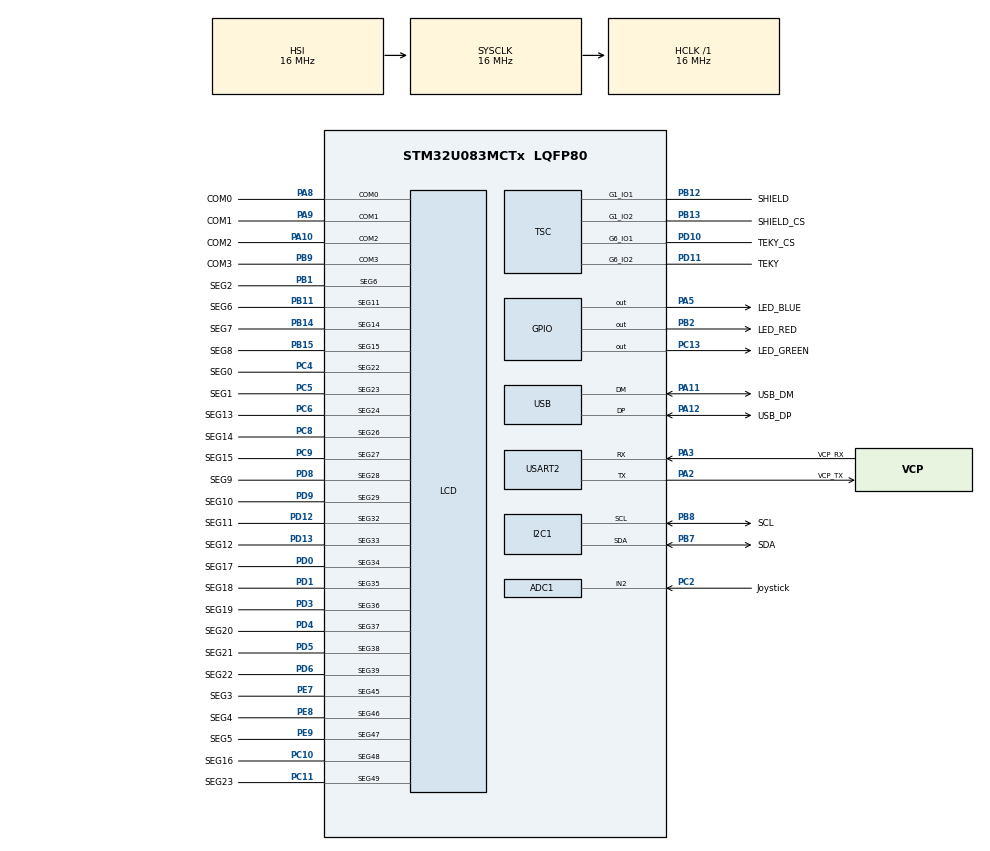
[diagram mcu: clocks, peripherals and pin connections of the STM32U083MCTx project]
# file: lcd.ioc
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ADC1.Channel-1\#ChannelRegularConversion=ADC_CHANNEL_2
ADC1.NbrOfConversionFlag=1
ADC1.Rank-1\#ChannelRegularConversion=1
ADC1.RankArg-1\#ChannelRegularConversion=ADC_REGULAR_RANK_1
ADC1.SamplingTime-1\#ChannelRegularConversion=ADC_SAMPLINGTIME_COMMON_1
ADC1.SelectedChannel=ADC_CHANNEL_2
ADC1.master=1
Mcu.Family=STM32U0
Mcu.Name=STM32U083MCTx
Mcu.Package=LQFP80
NVIC.PriorityGroup=NVIC_PRIORITYGROUP_2
PA10.GPIO_Label=COM2
PA10.Mode=1/4 Duty Cycle
PA10.Signal=LCD_COM2
PA11\ [PA9].GPIO_Label=USB_DM
PA11\ [PA9].Mode=Device
PA11\ [PA9].Signal=USB_DM
PA12\ [PA10].GPIO_Label=USB_DP
PA12\ [PA10].Mode=Device
PA12\ [PA10].Signal=USB_DP
PA13\ (SWDIO).GPIO_Label=SWDIO
PA13\ (SWDIO).Mode=Serial_Wire
PA13\ (SWDIO).Signal=DEBUG_JTMS-SWDIO
PA14\ (SWCLK).GPIO_Label=SWCLK
PA14\ (SWCLK).Mode=Serial_Wire
PA14\ (SWCLK).Signal=DEBUG_JTCK-SWCLK
PA2.GPIO_Label=VCP_TX
PA2.Mode=Asynchronous
PA2.Signal=USART2_TX
PA3.GPIO_Label=VCP_RX
PA3.Mode=Asynchronous
PA3.Signal=USART2_RX
PA5.GPIO_Label=LED_BLUE
PA5.Signal=GPIO_Output
PA8.GPIO_Label=COM0
PA8.Mode=1/4 Duty Cycle
PA8.Signal=LCD_COM0
PA9.GPIO_Label=COM1
PA9.Mode=1/4 Duty Cycle
PA9.Signal=LCD_COM1
PB1.GPIO_Label=SEG2
PB1.Mode=SEG6
PB1.Signal=LCD_SEG6
PB11.GPIO_Label=SEG6
PB11.Mode=SEG11
PB11.Signal=LCD_SEG11
PB12.GPIO_Label=SHIELD
PB12.Mode=G1_IO1-Sampling
PB12.Signal=TSC_G1_IO1
PB13.GPIO_Label=SHIELD_CS
PB13.Mode=G1_IO2-Channel
PB13.Signal=TSC_G1_IO2
PB14.GPIO_Label=SEG7
PB14.Mode=SEG14
PB14.Signal=LCD_SEG14
PB15.GPIO_Label=SEG8
PB15.Mode=SEG15
PB15.Signal=LCD_SEG15
PB2.GPIO_Label=LED_RED
PB2.Signal=GPIO_Output
PB7.GPIO_Label=SDA
PB7.Mode=I2C
PB7.Signal=I2C1_SDA
PB8.GPIO_Label=SCL
PB8.Mode=I2C
PB8.Signal=I2C1_SCL
PB9.GPIO_Label=COM3
PB9.Mode=1/4 Duty Cycle
PB9.Signal=LCD_COM3
PC10.GPIO_Label=SEG16
PC10.Mode=SEG48
PC10.Signal=LCD_SEG48
PC11.GPIO_Label=SEG23
PC11.Mode=SEG49
PC11.Signal=LCD_SEG49
PC13.GPIO_Label=LED_GREEN
PC13.Signal=GPIO_Output
PC14-OSC32_IN.GPIO_Label=OSC32_IN
PC14-OSC32_IN.Mode=LSE-External-Oscillator
PC14-OSC32_IN.Signal=RCC_OSC32_IN
PC15-OSC32_OUT.GPIO_Label=OSC32_OUT
PC15-OSC32_OUT.Mode=LSE-External-Oscillator
PC15-OSC32_OUT.Signal=RCC_OSC32_OUT
PC2.GPIO_Label=Joystick
PC2.Mode=IN2
PC2.Signal=ADC1_IN2
PC4.GPIO_Label=SEG0
PC4.Mode=SEG22
PC4.Signal=LCD_SEG22
PC5.GPIO_Label=SEG1
PC5.Mode=SEG23
PC5.Signal=LCD_SEG23
PC6.GPIO_Label=SEG13
PC6.Mode=SEG24
PC6.Signal=LCD_SEG24
PC8.GPIO_Label=SEG14
PC8.Mode=SEG26
PC8.Signal=LCD_SEG26
PC9.GPIO_Label=SEG15
PC9.Mode=SEG27
PC9.Signal=LCD_SEG27
PD0.GPIO_Label=SEG17
PD0.Mode=SEG34
PD0.Signal=LCD_SEG34
PD1.GPIO_Label=SEG18
PD1.Mode=SEG35
PD1.Signal=LCD_SEG35
PD10.GPIO_Label=TEKY_CS
PD10.Mode=G6_IO1-Sampling
PD10.Signal=TSC_G6_IO1
PD11.GPIO_Label=TEKY
PD11.Mode=G6_IO2-Shield
PD11.Signal=TSC_G6_IO2
PD12.GPIO_Label=SEG11
PD12.Mode=SEG32
PD12.Signal=LCD_SEG32
PD13.GPIO_Label=SEG12
PD13.Mode=SEG33
PD13.Signal=LCD_SEG33
PD3.GPIO_Label=SEG19
PD3.Mode=SEG36
PD3.Signal=LCD_SEG36
PD4.GPIO_Label=SEG20
PD4.Mode=SEG37
PD4.Signal=LCD_SEG37
PD5.GPIO_Label=SEG21
PD5.Mode=SEG38
PD5.Signal=LCD_SEG38
PD6.GPIO_Label=SEG22
PD6.Mode=SEG39
PD6.Signal=LCD_SEG39
PD8.GPIO_Label=SEG9
PD8.Mode=SEG28
PD8.Signal=LCD_SEG28
PD9.GPIO_Label=SEG10
PD9.Mode=SEG29
PD9.Signal=LCD_SEG29
PE7.GPIO_Label=SEG3
PE7.Mode=SEG45
PE7.Signal=LCD_SEG45
PE8.GPIO_Label=SEG4
PE8.Mode=SEG46
PE8.Signal=LCD_SEG46
PE9.GPIO_Label=SEG5
PE9.Mode=SEG47
PE9.Signal=LCD_SEG47
PF0-OSC_IN.GPIO_Label=OSC_IN
PF0-OSC_IN.Mode=HSE-External-Oscillator
PF0-OSC_IN.Signal=RCC_OSC_IN
PF1-OSC_OUT.GPIO_Label=OSC_OUT
PF1-OSC_OUT.Mode=HSE-External-Oscillator
PF1-OSC_OUT.Signal=RCC_OSC_OUT
ProjectManager.HeapSize=0x200
ProjectManager.StackSize=0x400
ProjectManager.TargetToolchain=STM32CubeIDE
RCC.AHBFreq_Value=16000000
RCC.CortexFreq_Value=16000000
RCC.HCLKFreq_Value=16000000
RCC.HSE_VALUE=4000000
RCC.HSI48_VALUE=48000000
RCC.HSI_VALUE=16000000
RCC.MSIClockRangeVal=RCC_MSIRANGE_11
RCC.MSI_VALUE=48000000
RCC.SYSCLKFreq_VALUE=16000000
RCC.USBFreq_Value=48000000
RCC.VCOOutputFreq_Value=64000000
USART2.VirtualMode-Asynchronous=VM_ASYNC
USB.VirtualMode=Device_Only
VP_PWR_VS_SECSignals.Mode=Security/Privilege
board=STM32U083C-DK

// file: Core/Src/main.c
/* USER CODE BEGIN Header */
/**
  ******************************************************************************
  * @file           : main.c
  * @brief          : Main program body
  ******************************************************************************
  * @attention
  *
  * Copyright (c) 2024 STMicroelectronics.
  * All rights reserved.
  *
  * This software is licensed under terms that can be found in the LICENSE file
  * in the root directory of this software component.
  * If no LICENSE file comes with this software, it is provided AS-IS.
  *
  ******************************************************************************
  */
/* USER CODE END Header */
#include "main.h"
#include "stm32u083c_discovery.h"
#include "stm32u083c_discovery_glass_lcd.h"
/* USER CODE BEGIN Includes */
uint8_t a[]= "hello ";
/* USER CODE END Includes */

ADC_HandleTypeDef hadc1;

I2C_HandleTypeDef hi2c1;

LCD_HandleTypeDef hlcd;

TSC_HandleTypeDef htsc;

UART_HandleTypeDef huart2;

PCD_HandleTypeDef hpcd_USB_DRD_FS;

void SystemClock_Config(void);
static void MX_GPIO_Init(void);
static void MX_ADC1_Init(void);
static void MX_I2C1_Init(void);
static void MX_LCD_Init(void);
static void MX_TSC_Init(void);
static void MX_USART2_UART_Init(void);
static void MX_USB_PCD_Init(void);

int main(void)
{

  /* MCU Configuration--------------------------------------------------------*/

  /* Reset of all peripherals, Initializes the Flash interface and the Systick. */
  HAL_Init();

  /* Configure the system clock */
  SystemClock_Config();

  /* Initialize all configured peripherals */
  MX_GPIO_Init();
  MX_ADC1_Init();
  MX_I2C1_Init();
 // MX_LCD_Init();
  MX_TSC_Init();
  MX_USART2_UART_Init();
  MX_USB_PCD_Init();
  /* USER CODE BEGIN 2 */
BSP_LCD_GLASS_Init();
BSP_LCD_GLASS_ScrollSentence(a, 1000, SCROLL_SPEED_LOW);
  /* USER CODE END 2 */

  /* Infinite loop */
  while (1)
  {

  }
}

void SystemClock_Config(void)
{
  RCC_OscInitTypeDef RCC_OscInitStruct = {0};
  RCC_ClkInitTypeDef RCC_ClkInitStruct = {0};

  /** Configure the main internal regulator output voltage
  */
  HAL_PWREx_ControlVoltageScaling(PWR_REGULATOR_VOLTAGE_SCALE2);

  /** Initializes the RCC Oscillators according to the specified parameters
  * in the RCC_OscInitTypeDef structure.
  */
  RCC_OscInitStruct.OscillatorType = RCC_OSCILLATORTYPE_HSI|RCC_OSCILLATORTYPE_MSI;
  RCC_OscInitStruct.HSIState = RCC_HSI_ON;
  RCC_OscInitStruct.HSICalibrationValue = RCC_HSICALIBRATION_DEFAULT;
  RCC_OscInitStruct.MSIState = RCC_MSI_ON;
  RCC_OscInitStruct.MSICalibrationValue = RCC_MSICALIBRATION_DEFAULT;
  RCC_OscInitStruct.MSIClockRange = RCC_MSIRANGE_11;
  RCC_OscInitStruct.PLL.PLLState = RCC_PLL_NONE;
  if (HAL_RCC_OscConfig(&RCC_OscInitStruct) != HAL_OK)
  {
    Error_Handler();
  }

  /** Initializes the CPU, AHB and APB buses clocks
  */
  RCC_ClkInitStruct.ClockType = RCC_CLOCKTYPE_HCLK|RCC_CLOCKTYPE_SYSCLK
                              |RCC_CLOCKTYPE_PCLK1;
  RCC_ClkInitStruct.SYSCLKSource = RCC_SYSCLKSOURCE_HSI;
  RCC_ClkInitStruct.AHBCLKDivider = RCC_SYSCLK_DIV1;
  RCC_ClkInitStruct.APB1CLKDivider = RCC_HCLK_DIV1;

  if (HAL_RCC_ClockConfig(&RCC_ClkInitStruct, FLASH_LATENCY_1) != HAL_OK)
  {
    Error_Handler();
  }
}

static void MX_ADC1_Init(void)
{

  ADC_ChannelConfTypeDef sConfig = {0};

  /** Configure the global features of the ADC (Clock, Resolution, Data Alignment and number of conversion)
  */
  hadc1.Instance = ADC1;
  hadc1.Init.ClockPrescaler = ADC_CLOCK_SYNC_PCLK_DIV1;
  hadc1.Init.Resolution = ADC_RESOLUTION_12B;
  hadc1.Init.DataAlign = ADC_DATAALIGN_RIGHT;
  hadc1.Init.ScanConvMode = ADC_SCAN_DISABLE;
  hadc1.Init.EOCSelection = ADC_EOC_SINGLE_CONV;
  hadc1.Init.LowPowerAutoWait = DISABLE;
  hadc1.Init.LowPowerAutoPowerOff = DISABLE;
  hadc1.Init.ContinuousConvMode = DISABLE;
  hadc1.Init.NbrOfConversion = 1;
  hadc1.Init.DiscontinuousConvMode = DISABLE;
  hadc1.Init.ExternalTrigConv = ADC_SOFTWARE_START;
  hadc1.Init.ExternalTrigConvEdge = ADC_EXTERNALTRIGCONVEDGE_NONE;
  hadc1.Init.DMAContinuousRequests = DISABLE;
  hadc1.Init.Overrun = ADC_OVR_DATA_PRESERVED;
  hadc1.Init.SamplingTimeCommon1 = ADC_SAMPLETIME_1CYCLE_5;
  hadc1.Init.SamplingTimeCommon2 = ADC_SAMPLETIME_1CYCLE_5;
  hadc1.Init.OversamplingMode = DISABLE;
  hadc1.Init.TriggerFrequencyMode = ADC_TRIGGER_FREQ_HIGH;
  if (HAL_ADC_Init(&hadc1) != HAL_OK)
  {
    Error_Handler();
  }

  /** Configure Regular Channel
  */
  sConfig.Channel = ADC_CHANNEL_2;
  sConfig.Rank = ADC_REGULAR_RANK_1;
  sConfig.SamplingTime = ADC_SAMPLINGTIME_COMMON_1;
  if (HAL_ADC_ConfigChannel(&hadc1, &sConfig) != HAL_OK)
  {
    Error_Handler();
  }

}

static void MX_I2C1_Init(void)
{

  hi2c1.Instance = I2C1;
  hi2c1.Init.Timing = 0x00000000;
  hi2c1.Init.OwnAddress1 = 0;
  hi2c1.Init.AddressingMode = I2C_ADDRESSINGMODE_7BIT;
  hi2c1.Init.DualAddressMode = I2C_DUALADDRESS_DISABLE;
  hi2c1.Init.OwnAddress2 = 0;
  hi2c1.Init.OwnAddress2Masks = I2C_OA2_NOMASK;
  hi2c1.Init.GeneralCallMode = I2C_GENERALCALL_DISABLE;
  hi2c1.Init.NoStretchMode = I2C_NOSTRETCH_DISABLE;
  if (HAL_I2C_Init(&hi2c1) != HAL_OK)
  {
    Error_Handler();
  }

  /** Configure Analogue filter
  */
  if (HAL_I2CEx_ConfigAnalogFilter(&hi2c1, I2C_ANALOGFILTER_ENABLE) != HAL_OK)
  {
    Error_Handler();
  }

  /** Configure Digital filter
  */
  if (HAL_I2CEx_ConfigDigitalFilter(&hi2c1, 0) != HAL_OK)
  {
    Error_Handler();
  }

}

static void MX_LCD_Init(void)
{

  hlcd.Instance = LCD;
  hlcd.Init.Prescaler = LCD_PRESCALER_1;
  hlcd.Init.Divider = LCD_DIVIDER_16;
  hlcd.Init.Duty = LCD_DUTY_1_4;
  hlcd.Init.Bias = LCD_BIAS_1_4;
  hlcd.Init.VoltageSource = LCD_VOLTAGESOURCE_INTERNAL;
  hlcd.Init.Contrast = LCD_CONTRASTLEVEL_0;
  hlcd.Init.DeadTime = LCD_DEADTIME_0;
  hlcd.Init.PulseOnDuration = LCD_PULSEONDURATION_0;
  hlcd.Init.BlinkMode = LCD_BLINKMODE_OFF;
  hlcd.Init.BlinkFrequency = LCD_BLINKFREQUENCY_DIV8;
  hlcd.Init.MuxSegment = LCD_MUXSEGMENT_DISABLE;
  if (HAL_LCD_Init(&hlcd) != HAL_OK)
  {
    Error_Handler();
  }

}

static void MX_TSC_Init(void)
{

  /** Configure the TSC peripheral
  */
  htsc.Instance = TSC;
  htsc.Init.CTPulseHighLength = TSC_CTPH_2CYCLES;
  htsc.Init.CTPulseLowLength = TSC_CTPL_2CYCLES;
  htsc.Init.SpreadSpectrum = DISABLE;
  htsc.Init.SpreadSpectrumDeviation = 1;
  htsc.Init.SpreadSpectrumPrescaler = TSC_SS_PRESC_DIV1;
  htsc.Init.PulseGeneratorPrescaler = TSC_PG_PRESC_DIV4;
  htsc.Init.MaxCountValue = TSC_MCV_8191;
  htsc.Init.IODefaultMode = TSC_IODEF_OUT_PP_LOW;
  htsc.Init.SynchroPinPolarity = TSC_SYNC_POLARITY_FALLING;
  htsc.Init.AcquisitionMode = TSC_ACQ_MODE_NORMAL;
  htsc.Init.MaxCountInterrupt = DISABLE;
  htsc.Init.ShieldIOs = TSC_GROUP6_IO2;
  htsc.Init.ChannelIOs = TSC_GROUP1_IO2;
  htsc.Init.SamplingIOs = TSC_GROUP1_IO1|TSC_GROUP6_IO1;
  if (HAL_TSC_Init(&htsc) != HAL_OK)
  {
    Error_Handler();
  }
  HAL_SYSCFG_DisableTSCComparatorMode();

}

static void MX_USART2_UART_Init(void)
{

  huart2.Instance = USART2;
  huart2.Init.BaudRate = 115200;
  huart2.Init.WordLength = UART_WORDLENGTH_8B;
  huart2.Init.StopBits = UART_STOPBITS_1;
  huart2.Init.Parity = UART_PARITY_NONE;
  huart2.Init.Mode = UART_MODE_TX_RX;
  huart2.Init.HwFlowCtl = UART_HWCONTROL_NONE;
  huart2.Init.OverSampling = UART_OVERSAMPLING_16;
  huart2.Init.OneBitSampling = UART_ONE_BIT_SAMPLE_DISABLE;
  huart2.Init.ClockPrescaler = UART_PRESCALER_DIV1;
  huart2.AdvancedInit.AdvFeatureInit = UART_ADVFEATURE_NO_INIT;
  if (HAL_UART_Init(&huart2) != HAL_OK)
  {
    Error_Handler();
  }
  if (HAL_UARTEx_SetTxFifoThreshold(&huart2, UART_TXFIFO_THRESHOLD_1_8) != HAL_OK)
  {
    Error_Handler();
  }
  if (HAL_UARTEx_SetRxFifoThreshold(&huart2, UART_RXFIFO_THRESHOLD_1_8) != HAL_OK)
  {
    Error_Handler();
  }
  if (HAL_UARTEx_DisableFifoMode(&huart2) != HAL_OK)
  {
    Error_Handler();
  }

}

static void MX_USB_PCD_Init(void)
{

  hpcd_USB_DRD_FS.Instance = USB_DRD_FS;
  hpcd_USB_DRD_FS.Init.dev_endpoints = 8;
  hpcd_USB_DRD_FS.Init.speed = USBD_FS_SPEED;
  hpcd_USB_DRD_FS.Init.phy_itface = PCD_PHY_EMBEDDED;
  hpcd_USB_DRD_FS.Init.Sof_enable = DISABLE;
  hpcd_USB_DRD_FS.Init.low_power_enable = DISABLE;
  hpcd_USB_DRD_FS.Init.lpm_enable = DISABLE;
  hpcd_USB_DRD_FS.Init.battery_charging_enable = DISABLE;
  if (HAL_PCD_Init(&hpcd_USB_DRD_FS) != HAL_OK)
  {
    Error_Handler();
  }

}

static void MX_GPIO_Init(void)
{
  GPIO_InitTypeDef GPIO_InitStruct = {0};

  /* GPIO Ports Clock Enable */
  __HAL_RCC_GPIOC_CLK_ENABLE();
  __HAL_RCC_GPIOF_CLK_ENABLE();
  __HAL_RCC_GPIOA_CLK_ENABLE();
  __HAL_RCC_GPIOB_CLK_ENABLE();
  __HAL_RCC_GPIOE_CLK_ENABLE();
  __HAL_RCC_GPIOD_CLK_ENABLE();

  /*Configure GPIO pin Output Level */
  HAL_GPIO_WritePin(LED_GREEN_GPIO_Port, LED_GREEN_Pin, GPIO_PIN_RESET);

  /*Configure GPIO pin Output Level */
  HAL_GPIO_WritePin(LED_BLUE_GPIO_Port, LED_BLUE_Pin, GPIO_PIN_RESET);

  /*Configure GPIO pin Output Level */
  HAL_GPIO_WritePin(LED_RED_GPIO_Port, LED_RED_Pin, GPIO_PIN_RESET);

  /*Configure GPIO pin : LED_GREEN_Pin */
  GPIO_InitStruct.Pin = LED_GREEN_Pin;
  GPIO_InitStruct.Mode = GPIO_MODE_OUTPUT_PP;
  GPIO_InitStruct.Pull = GPIO_NOPULL;
  GPIO_InitStruct.Speed = GPIO_SPEED_FREQ_LOW;
  HAL_GPIO_Init(LED_GREEN_GPIO_Port, &GPIO_InitStruct);

  /*Configure GPIO pin : LED_BLUE_Pin */
  GPIO_InitStruct.Pin = LED_BLUE_Pin;
  GPIO_InitStruct.Mode = GPIO_MODE_OUTPUT_PP;
  GPIO_InitStruct.Pull = GPIO_NOPULL;
  GPIO_InitStruct.Speed = GPIO_SPEED_FREQ_LOW;
  HAL_GPIO_Init(LED_BLUE_GPIO_Port, &GPIO_InitStruct);

  /*Configure GPIO pin : LED_RED_Pin */
  GPIO_InitStruct.Pin = LED_RED_Pin;
  GPIO_InitStruct.Mode = GPIO_MODE_OUTPUT_PP;
  GPIO_InitStruct.Pull = GPIO_NOPULL;
  GPIO_InitStruct.Speed = GPIO_SPEED_FREQ_LOW;
  HAL_GPIO_Init(LED_RED_GPIO_Port, &GPIO_InitStruct);

}

void Error_Handler(void)
{
  __disable_irq();
  while (1)
  {
  }
}
